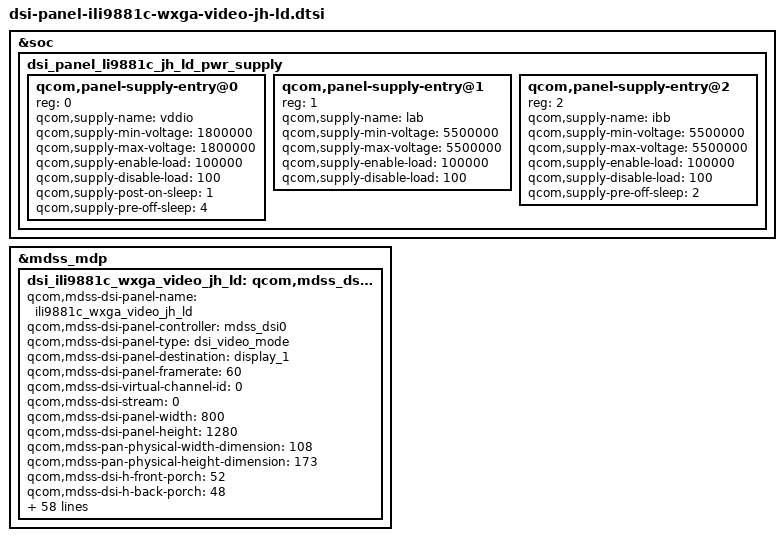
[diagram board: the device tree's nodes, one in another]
/* Copyright (c) 2013, The Linux Foundation. All rights reserved.
 *
 * This program is free software; you can redistribute it and/or modify
 * it under the terms of the GNU General Public License version 2 and
 * only version 2 as published by the Free Software Foundation.
 *
 * This program is distributed in the hope that it will be useful,
 * but WITHOUT ANY WARRANTY; without even the implied warranty of
 * MERCHANTABILITY or FITNESS FOR A PARTICULAR PURPOSE.  See the
 * GNU General Public License for more details.
 */

/*---------------------------------------------------------------------------
 * This file is autogenerated file using gcdb parser. Please do not edit it.
 * Update input XML file to add a new entry or update variable in this file
 * VERSION = "1.0"
 *---------------------------------------------------------------------------*/
&soc {
	dsi_panel_li9881c_jh_ld_pwr_supply: dsi_panel_li9881c_jh_ld_pwr_supply {
		#address-cells = <1>;
		#size-cells = <0>;

		qcom,panel-supply-entry@0 {
			reg = <0>;
			qcom,supply-name = "vddio";
			qcom,supply-min-voltage = <1800000>;
			qcom,supply-max-voltage = <1800000>;
			qcom,supply-enable-load = <100000>;
			qcom,supply-disable-load = <100>;
			qcom,supply-post-on-sleep = <1>;
			qcom,supply-pre-off-sleep = <4>;
		};

		qcom,panel-supply-entry@1 {
			reg = <1>;
			qcom,supply-name = "lab";
			qcom,supply-min-voltage = <5500000>;
			qcom,supply-max-voltage = <5500000>;
			qcom,supply-enable-load = <100000>;
			qcom,supply-disable-load = <100>;
			//qcom,supply-post-off-sleep = <1>;
		};

		qcom,panel-supply-entry@2 {
			reg = <2>;
			qcom,supply-name = "ibb";
			qcom,supply-min-voltage = <5500000>;
			qcom,supply-max-voltage = <5500000>;
			qcom,supply-enable-load = <100000>;
			qcom,supply-disable-load = <100>;
			qcom,supply-pre-off-sleep = <2>;
			//qcom,supply-post-on-sleep = <6>;
		};
	};
};
&mdss_mdp {
	dsi_ili9881c_wxga_video_jh_ld: qcom,mdss_dsi_ili9881c_wxga_video_jh_ld {
		qcom,mdss-dsi-panel-name = "ili9881c_wxga_video_jh_ld";
		qcom,mdss-dsi-panel-controller = <&mdss_dsi0>;
		qcom,mdss-dsi-panel-type = "dsi_video_mode";
		qcom,mdss-dsi-panel-destination = "display_1";
		qcom,mdss-dsi-panel-framerate = <60>;
		qcom,mdss-dsi-virtual-channel-id = <0>;
		qcom,mdss-dsi-stream = <0>;
		qcom,mdss-dsi-panel-width = <800>;
		qcom,mdss-dsi-panel-height = <1280>;
		qcom,mdss-pan-physical-width-dimension = <108>;
		qcom,mdss-pan-physical-height-dimension = <173>;
		qcom,mdss-dsi-h-front-porch = <52>;
		qcom,mdss-dsi-h-back-porch = <48>;
		qcom,mdss-dsi-h-pulse-width = <8>;
		qcom,mdss-dsi-h-sync-skew = <0>;
		qcom,mdss-dsi-v-back-porch = <15>;
		qcom,mdss-dsi-v-front-porch = <16>;
		qcom,mdss-dsi-v-pulse-width = <6>;
		qcom,mdss-dsi-h-left-border = <0>;
		qcom,mdss-dsi-h-right-border = <0>;
		qcom,mdss-dsi-v-top-border = <0>;
		qcom,mdss-dsi-v-bottom-border = <0>;
		qcom,mdss-dsi-bpp = <24>;
		qcom,mdss-dsi-color-order = "rgb_swap_rgb";
		qcom,mdss-dsi-underflow-color = <0xff>;
		qcom,mdss-dsi-border-color = <0>;
		qcom,mdss-dsi-on-command = [39 01 00 00 00 00 04 FF 98 81 03
					39 01 00 00 00 00 02 01 00
					39 01 00 00 00 00 02 02 00
					39 01 00 00 00 00 02 03 73
					39 01 00 00 00 00 02 04 00
					39 01 00 00 00 00 02 05 00
					39 01 00 00 00 00 02 06 0A
					39 01 00 00 00 00 02 07 00
					39 01 00 00 00 00 02 08 00
					39 01 00 00 00 00 02 09 20
					39 01 00 00 00 00 02 0A 20
					39 01 00 00 00 00 02 0B 00
					39 01 00 00 00 00 02 0C 00
					39 01 00 00 00 00 02 0D 00
					39 01 00 00 00 00 02 0E 00
					39 01 00 00 00 00 02 0F 1E
					39 01 00 00 00 00 02 10 1E
					39 01 00 00 00 00 02 11 00
					39 01 00 00 00 00 02 12 00
					39 01 00 00 00 00 02 13 00
					39 01 00 00 00 00 02 14 00
					39 01 00 00 00 00 02 15 10
					39 01 00 00 00 00 02 16 10
					39 01 00 00 00 00 02 17 03
					39 01 00 00 00 00 02 18 03
					39 01 00 00 00 00 02 19 00
					39 01 00 00 00 00 02 1A 00
					39 01 00 00 00 00 02 1B 00
					39 01 00 00 00 00 02 1C 00
					39 01 00 00 00 00 02 1D 00
					39 01 00 00 00 00 02 1E 40
					39 01 00 00 00 00 02 1F 80
					39 01 00 00 00 00 02 20 06
					39 01 00 00 00 00 02 21 01
					39 01 00 00 00 00 02 22 00
					39 01 00 00 00 00 02 23 00
					39 01 00 00 00 00 02 24 00
					39 01 00 00 00 00 02 25 00
					39 01 00 00 00 00 02 26 00
					39 01 00 00 00 00 02 27 00
					39 01 00 00 00 00 02 28 33
					39 01 00 00 00 00 02 29 03
					39 01 00 00 00 00 02 2A 00
					39 01 00 00 00 00 02 2B 00
					39 01 00 00 00 00 02 2C 00
					39 01 00 00 00 00 02 2D 00
					39 01 00 00 00 00 02 2E 00
					39 01 00 00 00 00 02 2F 00
					39 01 00 00 00 00 02 30 00
					39 01 00 00 00 00 02 31 00
					39 01 00 00 00 00 02 32 00
					39 01 00 00 00 00 02 33 00
					39 01 00 00 00 00 02 34 04
					39 01 00 00 00 00 02 35 00
					39 01 00 00 00 00 02 36 00
					39 01 00 00 00 00 02 37 00
					39 01 00 00 00 00 02 38 3C
					39 01 00 00 00 00 02 39 00
					39 01 00 00 00 00 02 3A 00
					39 01 00 00 00 00 02 3B 00
					39 01 00 00 00 00 02 3C 00
					39 01 00 00 00 00 02 3D 00
					39 01 00 00 00 00 02 3E 00
					39 01 00 00 00 00 02 3F 00
					39 01 00 00 00 00 02 40 00
					39 01 00 00 00 00 02 41 00
					39 01 00 00 00 00 02 42 00
					39 01 00 00 00 00 02 43 00
					39 01 00 00 00 00 02 44 00
					39 01 00 00 00 00 02 50 10
					39 01 00 00 00 00 02 51 32
					39 01 00 00 00 00 02 52 54
					39 01 00 00 00 00 02 53 76
					39 01 00 00 00 00 02 54 98
					39 01 00 00 00 00 02 55 ba
					39 01 00 00 00 00 02 56 10
					39 01 00 00 00 00 02 57 32
					39 01 00 00 00 00 02 58 54
					39 01 00 00 00 00 02 59 76
					39 01 00 00 00 00 02 5A 98
					39 01 00 00 00 00 02 5B ba
					39 01 00 00 00 00 02 5C dc
					39 01 00 00 00 00 02 5D fe
					39 01 00 00 00 00 02 5E 00
					39 01 00 00 00 00 02 5F 01
					39 01 00 00 00 00 02 60 00
					39 01 00 00 00 00 02 61 15
					39 01 00 00 00 00 02 62 14
					39 01 00 00 00 00 02 63 0E
					39 01 00 00 00 00 02 64 0F
					39 01 00 00 00 00 02 65 0C
					39 01 00 00 00 00 02 66 0D
					39 01 00 00 00 00 02 67 06
					39 01 00 00 00 00 02 68 02
					39 01 00 00 00 00 02 69 02
					39 01 00 00 00 00 02 6A 02
					39 01 00 00 00 00 02 6B 02
					39 01 00 00 00 00 02 6C 02
					39 01 00 00 00 00 02 6D 02
					39 01 00 00 00 00 02 6E 07
					39 01 00 00 00 00 02 6F 02
					39 01 00 00 00 00 02 70 02
					39 01 00 00 00 00 02 71 02
					39 01 00 00 00 00 02 72 02
					39 01 00 00 00 00 02 73 02
					39 01 00 00 00 00 02 74 02
					39 01 00 00 00 00 02 75 01
					39 01 00 00 00 00 02 76 00
					39 01 00 00 00 00 02 77 14
					39 01 00 00 00 00 02 78 15
					39 01 00 00 00 00 02 79 0E
					39 01 00 00 00 00 02 7A 0F
					39 01 00 00 00 00 02 7B 0C
					39 01 00 00 00 00 02 7C 0D
					39 01 00 00 00 00 02 7D 06
					39 01 00 00 00 00 02 7E 02
					39 01 00 00 00 00 02 7F 02
					39 01 00 00 00 00 02 80 02
					39 01 00 00 00 00 02 81 02
					39 01 00 00 00 00 02 82 02
					39 01 00 00 00 00 02 83 02
					39 01 00 00 00 00 02 84 07
					39 01 00 00 00 00 02 85 02
					39 01 00 00 00 00 02 86 02
					39 01 00 00 00 00 02 87 02
					39 01 00 00 00 00 02 88 02
					39 01 00 00 00 00 02 89 02
					39 01 00 00 00 00 02 8A 02
					39 01 00 00 00 00 04 FF 98 81 04
					39 01 00 00 00 00 02 6C 15
					39 01 00 00 00 00 02 6E 2A
					39 01 00 00 00 00 02 6F 35
					39 01 00 00 00 00 02 3A 24
					39 01 00 00 00 00 02 8D 1F
					39 01 00 00 00 00 02 87 BA
					39 01 00 00 00 00 02 26 76
					39 01 00 00 00 00 02 B2 D1
					39 01 00 00 00 00 02 B5 27
					39 01 00 00 00 00 02 31 75
					39 01 00 00 00 00 02 30 03
					39 01 00 00 00 00 02 3B 98
					39 01 00 00 00 00 02 35 1F
					39 01 00 00 00 00 02 33 14
					39 01 00 00 00 00 02 38 02
					39 01 00 00 00 00 02 39 00
					39 01 00 00 00 00 02 7A 0F
					39 01 00 00 00 00 04 FF 98 81 01
					39 01 00 00 00 00 02 22 0A
					39 01 00 00 00 00 02 31 00
					39 01 00 00 00 00 02 53 63
					39 01 00 00 00 00 02 55 69
					39 01 00 00 00 00 02 50 C7
					39 01 00 00 00 00 02 51 C2
					39 01 00 00 00 00 02 60 26
					39 01 00 00 00 00 02 63 00
					39 01 00 00 00 00 02 A0 08
					39 01 00 00 00 00 02 A1 0F
					39 01 00 00 00 00 02 A2 25
					39 01 00 00 00 00 02 A3 01
					39 01 00 00 00 00 02 A4 23
					39 01 00 00 00 00 02 A5 18
					39 01 00 00 00 00 02 A6 11
					39 01 00 00 00 00 02 A7 1A
					39 01 00 00 00 00 02 A8 81
					39 01 00 00 00 00 02 A9 19
					39 01 00 00 00 00 02 AA 26
					39 01 00 00 00 00 02 AB 7C
					39 01 00 00 00 00 02 AC 24
					39 01 00 00 00 00 02 AD 1E
					39 01 00 00 00 00 02 AE 5C
					39 01 00 00 00 00 02 AF 2A
					39 01 00 00 00 00 02 B0 2B
					39 01 00 00 00 00 02 B1 50
					39 01 00 00 00 00 02 B2 5C
					39 01 00 00 00 00 02 B3 39
					39 01 00 00 00 00 02 C0 08
					39 01 00 00 00 00 02 C1 1F
					39 01 00 00 00 00 02 C2 24
					39 01 00 00 00 00 02 C3 1D
					39 01 00 00 00 00 02 C4 04
					39 01 00 00 00 00 02 C5 32
					39 01 00 00 00 00 02 C6 24
					39 01 00 00 00 00 02 C7 1F
					39 01 00 00 00 00 02 C8 90
					39 01 00 00 00 00 02 C9 20
					39 01 00 00 00 00 02 CA 2C
					39 01 00 00 00 00 02 CB 82
					39 01 00 00 00 00 02 CC 19
					39 01 00 00 00 00 02 CD 22
					39 01 00 00 00 00 02 CE 4E
					39 01 00 00 00 00 02 CF 28
					39 01 00 00 00 00 02 D0 2D
					39 01 00 00 00 00 02 D1 51
					39 01 00 00 00 00 02 D2 5D
					39 01 00 00 00 00 02 D3 39
					39 01 00 00 00 00 04 FF 98 81 00
					05 01 00 00 78 00 02 11 00
					05 01 00 00 14 00 02 29 00
					39 01 00 00 00 00 02 35 00];
		qcom,mdss-dsi-off-command = [05 01 00 00 14 00 02 28 00
					05 01 00 00 78 00 02 10 00];
		qcom,mdss-dsi-on-command-state = "dsi_lp_mode";
		qcom,mdss-dsi-off-command-state = "dsi_lp_mode";
		qcom,mdss-dsi-h-sync-pulse = <1>;
		qcom,mdss-dsi-traffic-mode = "burst_mode";
		qcom,mdss-dsi-lane-map = "lane_map_0123";
		qcom,mdss-dsi-bllp-eof-power-mode;
		qcom,mdss-dsi-bllp-power-mode;
		qcom,mdss-dsi-lane-0-state;
		qcom,mdss-dsi-lane-1-state;
		qcom,mdss-dsi-lane-2-state;
		qcom,mdss-dsi-lane-3-state;
		qcom,mdss-dsi-panel-timings-phy-12nm = [09 06 09 02 00 04 02 08];
		//qcom,mdss-dsi-t-clk-post = <0x04>;
		//qcom,mdss-dsi-t-clk-pre = <0x1A>;
		qcom,mdss-dsi-dma-trigger = "trigger_sw";
		qcom,mdss-dsi-mdp-trigger = "none";
		qcom,mdss-dsi-bl-min-level = <1>;
		qcom,mdss-dsi-bl-max-level = <255>;
		qcom,mdss-dsi-bl-pmic-control-type = "bl_ctrl_pwm";
		qcom,mdss-dsi-bl-pmic-pwm-frequency = <50>;
		qcom,mdss-dsi-bl-pmic-bank-select = <0>;
		qcom,mdss-dsi-pwm-gpio = <&pm8953_gpios 8 0>;
		ss,blmap-size = <256>;
		ss,blmap = < 0 2 2 2 2 2 2 2 2 2
					2 2 3 3 4 5 6 7 8 9
					10 11 12 13 14 15 16 17 18 19
					20 21 22 23 24 25 26 27 28 29
					30 31 32 33 34 35 36 37 38 39
					40 41 42 43 44 45 46 47 48 49
					50 51 52 53 54 55 56 57 58 59
					60 61 62 63 64 65 66 67 68 69
					70 71 72 73 74 75 76 77 78 79
					80 81 82 83 84 85 86 87 88 89
					90 91 92 93 94 95 96 97 98 99
					100 101 102 103 104 105 106 107 108 109
					110 111 112 113 114 115 116 117 118 119
					120 121 122 123 124 125 126 127 128 129
					130 131 132 133 134 135 136 137 138 139
					140 141 142 143 144 145 146 147 148 149
					150 151 152 153 154 155 156 157 158 159
					160 161 162 163 164 165 166 167 168 169
					170 171 172 173 174 175 176 177 178 179
					180 181 182 183 184 185 186 187 188 189
					190 191 192 193 194 195 196 197 198 199
					200 201 202 203 204 205 206 207 208 209
					210 211 212 213 214 215 216 217 218 219
					220 221 222 223 224 225 226 227 228 229
					230 231 232 233 234 236 238 240 242 244
					246 248 250 252 254 255>;

		qcom,mdss-dsi-lp11-init;
		qcom,mdss-dsi-init-delay-us = <1000>;
		qcom,mdss-dsi-reset-sequence = <1 1>, <0 10>, <1 120>;
		qcom,esd-check-enabled;
		qcom,mdss-dsi-panel-status-command = [06 01 00 01 05 00 02 0A 08];
		qcom,mdss-dsi-panel-status-command-state = "dsi_lp_mode";
		qcom,mdss-dsi-panel-status-check-mode = "reg_read";
		qcom,mdss-dsi-panel-status-valid-params = <1>;
		qcom,mdss-dsi-panel-status-value = <0x9C>;
		qcom,mdss-dsi-panel-status-read-length = <1>;
		qcom,mdss-dsi-tx-eot-append;//bug601916, sheqihao.wt, MODIFY, 20201203, fix lcd abnormal after esd test 
		qcom,panel-supply-entries = <&dsi_panel_li9881c_jh_ld_pwr_supply>;
	};
};
